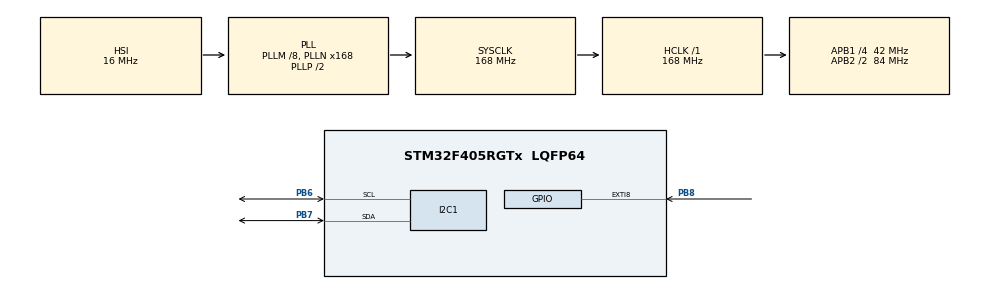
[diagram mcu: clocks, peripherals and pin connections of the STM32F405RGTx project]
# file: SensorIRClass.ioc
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I2C1.I2C_Mode=I2C_Fast
Mcu.Family=STM32F4
Mcu.Name=STM32F405RGTx
Mcu.Package=LQFP64
NVIC.EXTI9_5_IRQn=true\:0\:0\:true\:false\:true\:true\:true\:true
NVIC.PriorityGroup=NVIC_PRIORITYGROUP_4
PA13.Mode=Serial_Wire
PA13.Signal=SYS_JTMS-SWDIO
PA14.Mode=Serial_Wire
PA14.Signal=SYS_JTCK-SWCLK
PB6.Mode=I2C
PB6.Signal=I2C1_SCL
PB7.Mode=I2C
PB7.Signal=I2C1_SDA
PB8.GPIO_ModeDefaultEXTI=GPIO_MODE_IT_FALLING
PB8.Signal=GPXTI8
PH0-OSC_IN.Mode=HSE-External-Clock-Source
PH0-OSC_IN.Signal=RCC_OSC_IN
PH1-OSC_OUT.Mode=HSE-External-Clock-Source
PH1-OSC_OUT.Signal=RCC_OSC_OUT
ProjectManager.HeapSize=0x200
ProjectManager.StackSize=0x400
ProjectManager.TargetToolchain=STM32CubeIDE
RCC.48MHZClocksFreq_Value=84000000
RCC.AHBFreq_Value=168000000
RCC.APB1CLKDivider=RCC_HCLK_DIV4
RCC.APB1Freq_Value=42000000
RCC.APB1TimFreq_Value=84000000
RCC.APB2CLKDivider=RCC_HCLK_DIV2
RCC.APB2Freq_Value=84000000
RCC.APB2TimFreq_Value=168000000
RCC.CortexFreq_Value=168000000
RCC.HCLKFreq_Value=168000000
RCC.HSE_VALUE=25000000
RCC.HSI_VALUE=16000000
RCC.LSE_VALUE=32768
RCC.PLLM=8
RCC.PLLN=168
RCC.SYSCLKFreq_VALUE=168000000
RCC.SYSCLKSource=RCC_SYSCLKSOURCE_PLLCLK
RCC.VCOOutputFreq_Value=336000000
TIM1.Prescaler=71
VP_TIM1_VS_ClockSourceINT.Mode=Internal
board=custom

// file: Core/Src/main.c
/* USER CODE BEGIN Header */
/**
  ******************************************************************************
  * @file           : main.c
  * @brief          : Main program body
  ******************************************************************************
  * @attention
  *
  * Copyright (c) 2022 STMicroelectronics.
  * All rights reserved.
  *
  * This software is licensed under terms that can be found in the LICENSE file
  * in the root directory of this software component.
  * If no LICENSE file comes with this software, it is provided AS-IS.
  *
  ******************************************************************************
  */
/* USER CODE END Header */
#include "main.h"

/* USER CODE BEGIN Includes */
#include "fonts.h"
#include "ssd1306.h"
/* USER CODE END Includes */

 I2C_HandleTypeDef hi2c1;

TIM_HandleTypeDef htim1;

/* USER CODE BEGIN PV */
 uint32_t tempCode;
 uint8_t bitIndex;
 uint8_t cmd;
 uint8_t cmdli;
 uint32_t code;
/* USER CODE END PV */

void SystemClock_Config(void);
static void MX_GPIO_Init(void);
static void MX_I2C1_Init(void);
static void MX_TIM1_Init(void);

int main(void)
{

  /* MCU Configuration--------------------------------------------------------*/

  /* Reset of all peripherals, Initializes the Flash interface and the Systick. */
  HAL_Init();

  /* Configure the system clock */
  SystemClock_Config();

  /* Initialize all configured peripherals */
  MX_GPIO_Init();
  MX_I2C1_Init();
  MX_TIM1_Init();
  /* USER CODE BEGIN 2 */
  SSD1306_Init();
  HAL_TIM_Base_Start(&htim1);
  __HAL_TIM_SET_COUNTER(&htim1, 0);
  /* USER CODE END 2 */

  /* Infinite loop */
  while (1)
  {

  }
}

void SystemClock_Config(void)
{
  RCC_OscInitTypeDef RCC_OscInitStruct = {0};
  RCC_ClkInitTypeDef RCC_ClkInitStruct = {0};

  /** Configure the main internal regulator output voltage
  */
  __HAL_RCC_PWR_CLK_ENABLE();
  __HAL_PWR_VOLTAGESCALING_CONFIG(PWR_REGULATOR_VOLTAGE_SCALE1);

  /** Initializes the RCC Oscillators according to the specified parameters
  * in the RCC_OscInitTypeDef structure.
  */
  RCC_OscInitStruct.OscillatorType = RCC_OSCILLATORTYPE_HSI;
  RCC_OscInitStruct.HSIState = RCC_HSI_ON;
  RCC_OscInitStruct.HSICalibrationValue = RCC_HSICALIBRATION_DEFAULT;
  RCC_OscInitStruct.PLL.PLLState = RCC_PLL_ON;
  RCC_OscInitStruct.PLL.PLLSource = RCC_PLLSOURCE_HSI;
  RCC_OscInitStruct.PLL.PLLM = 8;
  RCC_OscInitStruct.PLL.PLLN = 168;
  RCC_OscInitStruct.PLL.PLLP = RCC_PLLP_DIV2;
  RCC_OscInitStruct.PLL.PLLQ = 4;
  if (HAL_RCC_OscConfig(&RCC_OscInitStruct) != HAL_OK)
  {
    Error_Handler();
  }

  /** Initializes the CPU, AHB and APB buses clocks
  */
  RCC_ClkInitStruct.ClockType = RCC_CLOCKTYPE_HCLK|RCC_CLOCKTYPE_SYSCLK
                              |RCC_CLOCKTYPE_PCLK1|RCC_CLOCKTYPE_PCLK2;
  RCC_ClkInitStruct.SYSCLKSource = RCC_SYSCLKSOURCE_PLLCLK;
  RCC_ClkInitStruct.AHBCLKDivider = RCC_SYSCLK_DIV1;
  RCC_ClkInitStruct.APB1CLKDivider = RCC_HCLK_DIV4;
  RCC_ClkInitStruct.APB2CLKDivider = RCC_HCLK_DIV2;

  if (HAL_RCC_ClockConfig(&RCC_ClkInitStruct, FLASH_LATENCY_5) != HAL_OK)
  {
    Error_Handler();
  }
}

static void MX_I2C1_Init(void)
{

  hi2c1.Instance = I2C1;
  hi2c1.Init.ClockSpeed = 400000;
  hi2c1.Init.DutyCycle = I2C_DUTYCYCLE_2;
  hi2c1.Init.OwnAddress1 = 0;
  hi2c1.Init.AddressingMode = I2C_ADDRESSINGMODE_7BIT;
  hi2c1.Init.DualAddressMode = I2C_DUALADDRESS_DISABLE;
  hi2c1.Init.OwnAddress2 = 0;
  hi2c1.Init.GeneralCallMode = I2C_GENERALCALL_DISABLE;
  hi2c1.Init.NoStretchMode = I2C_NOSTRETCH_DISABLE;
  if (HAL_I2C_Init(&hi2c1) != HAL_OK)
  {
    Error_Handler();
  }

}

static void MX_TIM1_Init(void)
{

  TIM_ClockConfigTypeDef sClockSourceConfig = {0};
  TIM_MasterConfigTypeDef sMasterConfig = {0};

  htim1.Instance = TIM1;
  htim1.Init.Prescaler = 71;
  htim1.Init.CounterMode = TIM_COUNTERMODE_UP;
  htim1.Init.Period = 65535;
  htim1.Init.ClockDivision = TIM_CLOCKDIVISION_DIV1;
  htim1.Init.RepetitionCounter = 0;
  htim1.Init.AutoReloadPreload = TIM_AUTORELOAD_PRELOAD_DISABLE;
  if (HAL_TIM_Base_Init(&htim1) != HAL_OK)
  {
    Error_Handler();
  }
  sClockSourceConfig.ClockSource = TIM_CLOCKSOURCE_INTERNAL;
  if (HAL_TIM_ConfigClockSource(&htim1, &sClockSourceConfig) != HAL_OK)
  {
    Error_Handler();
  }
  sMasterConfig.MasterOutputTrigger = TIM_TRGO_RESET;
  sMasterConfig.MasterSlaveMode = TIM_MASTERSLAVEMODE_DISABLE;
  if (HAL_TIMEx_MasterConfigSynchronization(&htim1, &sMasterConfig) != HAL_OK)
  {
    Error_Handler();
  }

}

static void MX_GPIO_Init(void)
{
  GPIO_InitTypeDef GPIO_InitStruct = {0};

  /* GPIO Ports Clock Enable */
  __HAL_RCC_GPIOH_CLK_ENABLE();
  __HAL_RCC_GPIOA_CLK_ENABLE();
  __HAL_RCC_GPIOB_CLK_ENABLE();

  /*Configure GPIO pin : PB8 */
  GPIO_InitStruct.Pin = GPIO_PIN_8;
  GPIO_InitStruct.Mode = GPIO_MODE_IT_FALLING;
  GPIO_InitStruct.Pull = GPIO_NOPULL;
  HAL_GPIO_Init(GPIOB, &GPIO_InitStruct);

  /* EXTI interrupt init*/
  HAL_NVIC_SetPriority(EXTI9_5_IRQn, 0, 0);
  HAL_NVIC_EnableIRQ(EXTI9_5_IRQn);

}

/* USER CODE BEGIN 4 */
void HAL_GPIO_EXTI_Callback(uint16_t GPIO_Pin)
{
  if(GPIO_Pin == GPIO_PIN_11)
  {
    if (__HAL_TIM_GET_COUNTER(&htim1) > 8000)
    {
      tempCode = 0;
      bitIndex = 0;
    }
    else if (__HAL_TIM_GET_COUNTER(&htim1) > 1700)
    {
      tempCode |= (1UL << (31-bitIndex));   // write 1
      bitIndex++;
    }
    else if (__HAL_TIM_GET_COUNTER(&htim1) > 1000)
    {
      tempCode &= ~(1UL << (31-bitIndex));  // write 0
      bitIndex++;
    }
    if(bitIndex == 32)
    {
      cmdli = ~tempCode; // Logical inverted last 8 bits
      cmd = tempCode >> 8; // Second last 8 bits
      if(cmdli == cmd) // Check for errors
      {
        code = tempCode; // If no bit errors
        // Do your main work HERE
        SSD1306_Clear();
        SSD1306_GotoXY (0, 20);
        char snum[10];
        itoa(code, snum, 10);
        SSD1306_Puts (snum, &Font_11x18, 1);
        SSD1306_UpdateScreen();
      }
      bitIndex = 0;
    }
    __HAL_TIM_SET_COUNTER(&htim1, 0);
  }
}
/* USER CODE END 4 */

void Error_Handler(void)
{
  __disable_irq();
  while (1)
  {
  }
}
